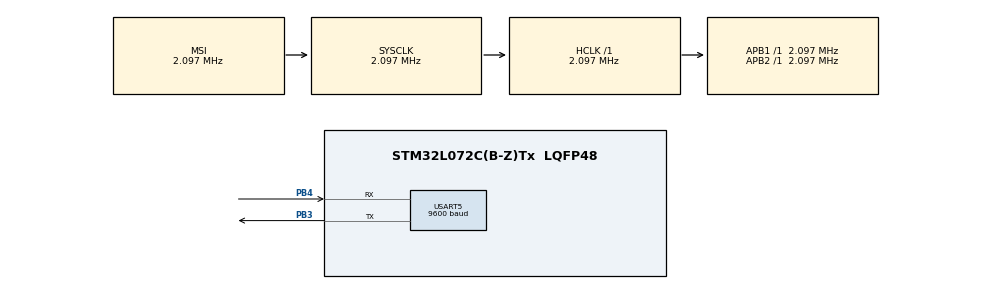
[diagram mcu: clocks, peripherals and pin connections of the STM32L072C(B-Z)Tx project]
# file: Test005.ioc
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Mcu.Family=STM32L0
Mcu.Name=STM32L072C(B-Z)Tx
Mcu.Package=LQFP48
PA13.Mode=Serial_Wire
PA13.Signal=SYS_SWDIO
PA14.Mode=Serial_Wire
PA14.Signal=SYS_SWCLK
PB3.Mode=Asynchronous
PB3.Signal=USART5_TX
PB4.Mode=Asynchronous
PB4.Signal=USART5_RX
ProjectManager.HeapSize=0x200
ProjectManager.StackSize=0x400
ProjectManager.TargetToolchain=STM32CubeIDE
RCC.AHBFreq_Value=2097000
RCC.APB1Freq_Value=2097000
RCC.APB1TimFreq_Value=2097000
RCC.APB2Freq_Value=2097000
RCC.APB2TimFreq_Value=2097000
RCC.HSE_VALUE=8000000
RCC.HSI16_VALUE=16000000
RCC.HSI48_VALUE=48000000
RCC.HSI_VALUE=16000000
RCC.LSE_VALUE=32768
RCC.MSI_VALUE=2097000
RCC.SYSCLKFreq_VALUE=2097000
RCC.VCOOutputFreq_Value=48000000
USART5.BaudRate=9600
USART5.VirtualMode-Asynchronous=VM_ASYNC
board=custom

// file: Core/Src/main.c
/* USER CODE BEGIN Header */
/**
 * printf redirection to UART_DBG
 * Works only with "/n"
 * Based on BDM board with STM32L072CBTx
  ******************************************************************************
  * @file           : main.c
  * @brief          : Main program body
  ******************************************************************************
  * @attention
  *
  * <h2><center>&copy; Copyright (c) 2021 STMicroelectronics.
  * All rights reserved.</center></h2>
  *
  * This software component is licensed by ST under BSD 3-Clause license,
  * the "License"; You may not use this file except in compliance with the
  * License. You may obtain a copy of the License at:
  *                        opensource.org/licenses/BSD-3-Clause
  *
  ******************************************************************************
  */
/* USER CODE END Header */
#include "main.h"

/* USER CODE BEGIN Includes */

// printf redirection to UART_DBG
#include <stdio.h>
#include <string.h>
/* USER CODE END Includes */

/* USER CODE BEGIN PD */
#define     UART_DBG                    huart5
#define 	HAL_UART_DBG_TO_DUR			1000
/* USER CODE END PD */

UART_HandleTypeDef huart5;

/* USER CODE BEGIN PV */

// printf redirection to UART_DBG
const char* s = "float" ;
float f = 1.101 ;
/* USER CODE END PV */

void SystemClock_Config(void);
static void MX_GPIO_Init(void);
static void MX_USART5_UART_Init(void);
/* USER CODE BEGIN PFP */

// printf redirection to UART_DBG
#define PUTCHAR_PROTOTYPE int fputc ( int ch , FILE* f )

/* USER CODE END PFP */

int main(void)
{

  /* MCU Configuration--------------------------------------------------------*/

  /* Reset of all peripherals, Initializes the Flash interface and the Systick. */
  HAL_Init();

  /* Configure the system clock */
  SystemClock_Config();

  /* Initialize all configured peripherals */
  MX_GPIO_Init();
  MX_USART5_UART_Init();
  /* USER CODE BEGIN 2 */

	// printf redirection to UART_DBG test
	//printf ( "Value of %s is: %f\r\n" , s , f ) ;
	printf ( "Value\r\n" ) ;

  /* USER CODE END 2 */

  /* Infinite loop */
  while (1)
  {

  }
}

void SystemClock_Config(void)
{
  RCC_OscInitTypeDef RCC_OscInitStruct = {0};
  RCC_ClkInitTypeDef RCC_ClkInitStruct = {0};

  /** Configure the main internal regulator output voltage
  */
  __HAL_PWR_VOLTAGESCALING_CONFIG(PWR_REGULATOR_VOLTAGE_SCALE1);
  /** Initializes the RCC Oscillators according to the specified parameters
  * in the RCC_OscInitTypeDef structure.
  */
  RCC_OscInitStruct.OscillatorType = RCC_OSCILLATORTYPE_MSI;
  RCC_OscInitStruct.MSIState = RCC_MSI_ON;
  RCC_OscInitStruct.MSICalibrationValue = 0;
  RCC_OscInitStruct.MSIClockRange = RCC_MSIRANGE_5;
  RCC_OscInitStruct.PLL.PLLState = RCC_PLL_NONE;
  if (HAL_RCC_OscConfig(&RCC_OscInitStruct) != HAL_OK)
  {
    Error_Handler();
  }
  /** Initializes the CPU, AHB and APB buses clocks
  */
  RCC_ClkInitStruct.ClockType = RCC_CLOCKTYPE_HCLK|RCC_CLOCKTYPE_SYSCLK
                              |RCC_CLOCKTYPE_PCLK1|RCC_CLOCKTYPE_PCLK2;
  RCC_ClkInitStruct.SYSCLKSource = RCC_SYSCLKSOURCE_MSI;
  RCC_ClkInitStruct.AHBCLKDivider = RCC_SYSCLK_DIV1;
  RCC_ClkInitStruct.APB1CLKDivider = RCC_HCLK_DIV1;
  RCC_ClkInitStruct.APB2CLKDivider = RCC_HCLK_DIV1;

  if (HAL_RCC_ClockConfig(&RCC_ClkInitStruct, FLASH_LATENCY_0) != HAL_OK)
  {
    Error_Handler();
  }
}

static void MX_USART5_UART_Init(void)
{

  huart5.Instance = USART5;
  huart5.Init.BaudRate = 9600;
  huart5.Init.WordLength = UART_WORDLENGTH_8B;
  huart5.Init.StopBits = UART_STOPBITS_1;
  huart5.Init.Parity = UART_PARITY_NONE;
  huart5.Init.Mode = UART_MODE_TX_RX;
  huart5.Init.HwFlowCtl = UART_HWCONTROL_NONE;
  huart5.Init.OverSampling = UART_OVERSAMPLING_16;
  huart5.Init.OneBitSampling = UART_ONE_BIT_SAMPLE_DISABLE;
  huart5.AdvancedInit.AdvFeatureInit = UART_ADVFEATURE_NO_INIT;
  if (HAL_UART_Init(&huart5) != HAL_OK)
  {
    Error_Handler();
  }

}

static void MX_GPIO_Init(void)
{

  /* GPIO Ports Clock Enable */
  __HAL_RCC_GPIOA_CLK_ENABLE();
  __HAL_RCC_GPIOB_CLK_ENABLE();

}

/* USER CODE BEGIN 4 */

PUTCHAR_PROTOTYPE
{
	HAL_UART_Transmit ( &UART_DBG , (uint8_t*) &ch , 1 , HAL_UART_DBG_TO_DUR ) ;
	return ch ;
}

/* USER CODE END 4 */

void Error_Handler(void)
{
  __disable_irq();
  while (1)
  {
  }
}

/************************ (C) COPYRIGHT STMicroelectronics *****END OF FILE****/
